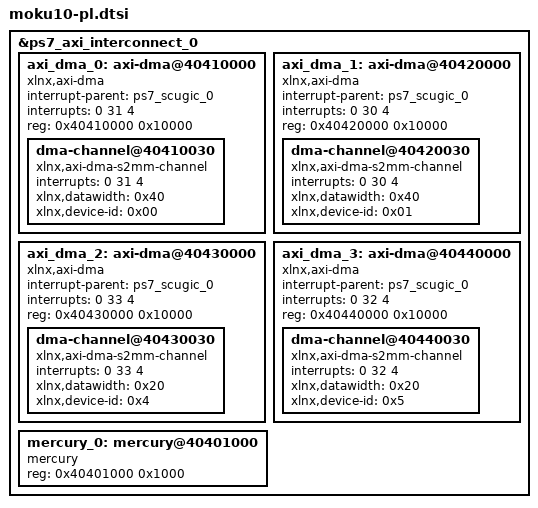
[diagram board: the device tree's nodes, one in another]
/*
 * CAUTION: This file is automatically generated by Xilinx.
 * Version:  
 * Today is: Wed Dec  3 15:57:26 2014
*/

	&ps7_axi_interconnect_0 {
		ranges;
		axi_dma_0: axi-dma@40410000 {
			compatible = "xlnx,axi-dma";
			interrupt-parent = <&ps7_scugic_0>;
			interrupts = <0 31 4>;
			reg = <0x40410000 0x10000>;
			dma-channel@40410030 {
				compatible = "xlnx,axi-dma-s2mm-channel";
				interrupts = <0 31 4>;
				xlnx,datawidth = <0x40>;
				xlnx,device-id = <0x00>;
			} ;
		} ;
		axi_dma_1: axi-dma@40420000 {
			compatible = "xlnx,axi-dma";
			interrupt-parent = <&ps7_scugic_0>;
			interrupts = <0 30 4>;
			reg = <0x40420000 0x10000>;
			dma-channel@40420030 {
				compatible = "xlnx,axi-dma-s2mm-channel";
				interrupts = <0 30 4>;
				xlnx,datawidth = <0x40>;
				xlnx,device-id = <0x01>;
			} ;
		} ;
		axi_dma_2: axi-dma@40430000 {
			compatible = "xlnx,axi-dma";
			interrupt-parent = <&ps7_scugic_0>;
			interrupts = <0 33 4>;
			reg = <0x40430000 0x10000>;
			dma-channel@40430030 {
				compatible = "xlnx,axi-dma-s2mm-channel";
				interrupts = <0 33 4>;
				xlnx,datawidth = <0x20>;
				xlnx,device-id = <0x4>;
			};
		};
		axi_dma_3: axi-dma@40440000 {
			compatible = "xlnx,axi-dma";
			interrupt-parent = <&ps7_scugic_0>;
			interrupts = <0 32 4>;
			reg = <0x40440000 0x10000>;
			dma-channel@40440030 {
				compatible = "xlnx,axi-dma-s2mm-channel";
				interrupts = <0 32 4>;
				xlnx,datawidth = <0x20>;
				xlnx,device-id = <0x5>;
			};
		};

		mercury_0: mercury@40401000 {
			compatible = "mercury";
			reg = <0x40401000 0x1000>;
		} ;
	} ;
